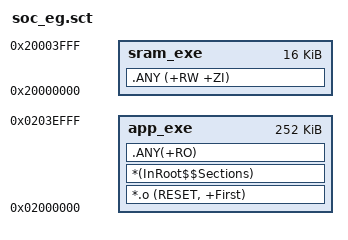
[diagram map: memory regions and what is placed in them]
LR_IROM1 0x02000000 0x3f000
{
    app_exe 0x02000000 0x3f000
    {
        *.o (RESET, +First)
        *(InRoot$$Sections)
        .ANY(+RO)
    }

    sram_exe 0x20000000 0x4000
    {
        .ANY (+RW +ZI)
    }
}

